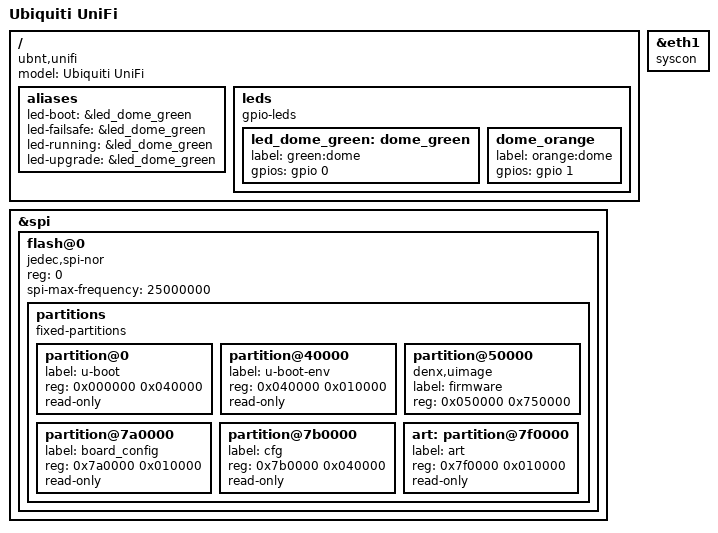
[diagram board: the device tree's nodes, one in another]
// SPDX-License-Identifier: GPL-2.0-or-later OR MIT

#include "ar7241_ubnt_unifi.dtsi"

/ {
	compatible = "ubnt,unifi", "qca,ar7241";
	model = "Ubiquiti UniFi";

	aliases {
		led-boot = &led_dome_green;
		led-failsafe = &led_dome_green;
		led-running = &led_dome_green;
		led-upgrade = &led_dome_green;
	};

	leds {
		compatible = "gpio-leds";

		led_dome_green: dome_green {
			label = "green:dome";
			gpios = <&gpio 0 GPIO_ACTIVE_HIGH>;
		};

		dome_orange {
			label = "orange:dome";
			gpios = <&gpio 1 GPIO_ACTIVE_HIGH>;
		};
	};
};

&spi {
	status = "okay";

	flash@0 {
		compatible = "jedec,spi-nor";
		reg = <0>;
		spi-max-frequency = <25000000>;

		partitions {
			compatible = "fixed-partitions";
			#address-cells = <1>;
			#size-cells = <1>;

			partition@0 {
				label = "u-boot";
				reg = <0x000000 0x040000>;
				read-only;
			};

			partition@40000 {
				label = "u-boot-env";
				reg = <0x040000 0x010000>;
				read-only;
			};

			partition@50000 {
				compatible = "denx,uimage";
				label = "firmware";
				reg = <0x050000 0x750000>;
			};

			partition@7a0000 {
				label = "board_config";
				reg = <0x7a0000 0x010000>;
				read-only;
			};

			partition@7b0000 {
				label = "cfg";
				reg = <0x7b0000 0x040000>;
				read-only;
			};

			art: partition@7f0000 {
				label = "art";
				reg = <0x7f0000 0x010000>;
				read-only;
			};
		};
	};
};

&eth1 {
	compatible = "syscon", "simple-mfd";
};
